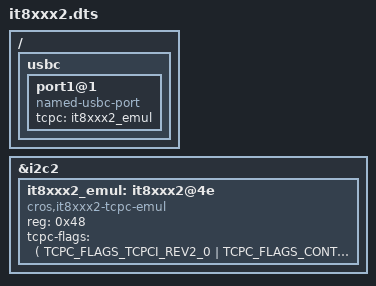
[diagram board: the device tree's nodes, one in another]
/* Copyright 2025 The ChromiumOS Authors
 * Use of this source code is governed by a BSD-style license that can be
 * found in the LICENSE file.
 */

#include <dt-bindings/usb_pd_tcpm.h>

/ {
	usbc {
		port1@1 {
			compatible = "named-usbc-port";
			tcpc = <&it8xxx2_emul>;
		};
	};
};

&i2c2 {
	status="okay";

	it8xxx2_emul: it8xxx2@4e {
		compatible = "cros,it8xxx2-tcpc-emul", "ite,it8xxx2-tcpc";
		status = "okay";
		reg = <0x48>;
		tcpc-flags = <(
			TCPC_FLAGS_TCPCI_REV2_0 |
			TCPC_FLAGS_CONTROL_VCONN |
			TCPC_FLAGS_TCPCI_REV2_0_NO_VSAFE0V)>;
	};
};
